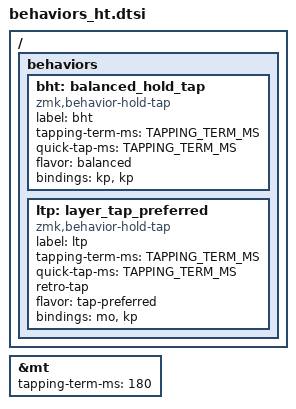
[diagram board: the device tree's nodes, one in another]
#include <behaviors.dtsi>
#include <dt-bindings/zmk/keys.h>

#define TAPPING_TERM_MS 300
#define TAPPING_TERM_MS_FAST 180
#define TAPPING_TERM_MS_SLOW 600

&mt {
    tapping-term-ms = <180>;
};

/ {
    behaviors {
        bht: balanced_hold_tap {
            compatible = "zmk,behavior-hold-tap";
            label = "bht";
            #binding-cells = <2>;
            tapping-term-ms = <TAPPING_TERM_MS>;
            quick-tap-ms = <TAPPING_TERM_MS>;
            flavor = "balanced";
            bindings = <&kp>, <&kp>;
        };

        ltp: layer_tap_preferred {
            compatible = "zmk,behavior-hold-tap";
            label = "ltp";
            #binding-cells = <2>;
            tapping-term-ms = <TAPPING_TERM_MS>;
            quick-tap-ms = <TAPPING_TERM_MS>;
            retro-tap;
            flavor = "tap-preferred";
            bindings = <&mo>, <&kp>;
        };
    };
};
